AUTOSAR XML (schema 321)
# Copyright © Vector Informatik GmbH 2014
# The usage of this tool (CBD1300649 D00) is restricted to:
# - FOR THE ECU-PROJECT EPS
# - FOR THE OEM FIAT
# Please contact Vector Informatik whenever you need further information concerning the license conditions.
package /VehicleProject
  system System: fibex-element=[CCAN, EPS, EPS__CCAN_Rx, EPS__CCAN_Tx, BCM_COMMAND__CCAN, BSM1__CCAN, CFG_DATA_CODE_REQUEST__CCAN, CFG_DATA_CODE_RSP_EPS__CCAN, DIAGNOSTIC_REQUEST_EPS__CCAN, DIAGNOSTIC_REQUEST_FUNCTIONAL__CCAN, DIAGNOSTIC_RESPONSE_EPS__CCAN, GE__CCAN, GliwaMaster__CCAN, GliwaSlave__CCAN, MOT1__CCAN, MOT3__CCAN, NM_BCM__CCAN, NM_BSM__CCAN, NM_ECM__CCAN, NM_EPS__CCAN, NM_IPC__CCAN, NM_TRANSMISSION__CCAN, PDC_INFO_EPS__CCAN, STATUS_C_BCM2__CCAN, STATUS_C_IPC__CCAN, XcpMaster__CCAN, XcpSlave__CCAN, BCM_COMMAND__CCAN, BSM1__CCAN, CFG_DATA_CODE_REQUEST__CCAN, CFG_DATA_CODE_RSP_EPS__CCAN, GE__CCAN, GliwaMaster__CCAN, GliwaSlave__CCAN, MOT1__CCAN, MOT3__CCAN, PDC_INFO_EPS__CCAN, STATUS_C_BCM2__CCAN, STATUS_C_IPC__CCAN, XcpMaster__CCAN, XcpSlave__CCAN, DIAGNOSTIC_REQUEST_EPS__CCAN, DIAGNOSTIC_REQUEST_FUNCTIONAL__CCAN, DIAGNOSTIC_RESPONSE_EPS__CCAN, NM_BCM__CCAN, NM_BSM__CCAN, NM_ECM__CCAN, NM_EPS__CCAN, NM_IPC__CCAN, NM_TRANSMISSION__CCAN, DIAGNOSTIC_REQUEST_EPS_Tp__CCAN, DIAGNOSTIC_REQUEST_FUNCTIONAL_Tp__CCAN, DIAGNOSTIC_RESPONSE_EPS_Tp__CCAN, CityModeSts__STATUS_C_BCM2__CCAN, CmdIgn_FailSts__STATUS_C_BCM2__CCAN, CmdIgnSts__STATUS_C_BCM2__CCAN, CRC_B1__BSM1__CCAN, CurrentFailSts_EPS__PDC_INFO_EPS__CCAN, DES_EPS__PDC_INFO_EPS__CCAN, Digit_01__CFG_DATA_CODE_REQUEST__CCAN, Digit_01_EPS__CFG_DATA_CODE_RSP_EPS__CCAN, Digit_02__CFG_DATA_CODE_REQUEST__CCAN, Digit_02_EPS__CFG_DATA_CODE_RSP_EPS__CCAN, Digit_03__CFG_DATA_CODE_REQUEST__CCAN, Digit_03_EPS__CFG_DATA_CODE_RSP_EPS__CCAN, Digit_04__CFG_DATA_CODE_REQUEST__CCAN, Digit_04_EPS__CFG_DATA_CODE_RSP_EPS__CCAN, Digit_05__CFG_DATA_CODE_REQUEST__CCAN, Digit_05_EPS__CFG_DATA_CODE_RSP_EPS__CCAN, Digit_06__CFG_DATA_CODE_REQUEST__CCAN, Digit_06_EPS__CFG_DATA_CODE_RSP_EPS__CCAN, Digit_07__CFG_DATA_CODE_REQUEST__CCAN, Digit_07_EPS__CFG_DATA_CODE_RSP_EPS__CCAN, Digit_08__CFG_DATA_CODE_REQUEST__CCAN, Digit_08_EPS__CFG_DATA_CODE_RSP_EPS__CCAN, Digit_09__CFG_DATA_CODE_REQUEST__CCAN, Digit_09_EPS__CFG_DATA_CODE_RSP_EPS__CCAN, Digit_10__CFG_DATA_CODE_REQUEST__CCAN, Digit_10_EPS__CFG_DATA_CODE_RSP_EPS__CCAN, Digit_11__CFG_DATA_CODE_REQUEST__CCAN, Digit_11_EPS__CFG_DATA_CODE_RSP_EPS__CCAN, ElectricSteeringFailSts__GE__CCAN, ElectricSteeringLamp_FailSts__STATUS_C_IPC__CCAN, EngineStopStartSts__MOT3__CCAN, EngineSts__MOT1__CCAN, EOL_EPS__PDC_INFO_EPS__CCAN, GenericFailSts_EPS__PDC_INFO_EPS__CCAN, LwsAngle__GE__CCAN, LwsAngleType__GE__CCAN, LwsCalibration__GE__CCAN, LWSFailSts__GE__CCAN, LwsSpeed__GE__CCAN, MessageCounter_B1__BSM1__CCAN, OperationalModeSts__BCM_COMMAND__CCAN, Reserved_for_PDC_EPS__PDC_INFO_EPS__CCAN, StayActiveSource_EPS_0__PDC_INFO_EPS__CCAN, StayActiveSource_EPS_1__PDC_INFO_EPS__CCAN, StayActiveSource_EPS_10__PDC_INFO_EPS__CCAN, StayActiveSource_EPS_11__PDC_INFO_EPS__CCAN, StayActiveSource_EPS_12__PDC_INFO_EPS__CCAN, StayActiveSource_EPS_13__PDC_INFO_EPS__CCAN, StayActiveSource_EPS_14__PDC_INFO_EPS__CCAN, StayActiveSource_EPS_15__PDC_INFO_EPS__CCAN, StayActiveSource_EPS_2__PDC_INFO_EPS__CCAN, StayActiveSource_EPS_3__PDC_INFO_EPS__CCAN, StayActiveSource_EPS_4__PDC_INFO_EPS__CCAN, StayActiveSource_EPS_5__PDC_INFO_EPS__CCAN, StayActiveSource_EPS_6__PDC_INFO_EPS__CCAN, StayActiveSource_EPS_7__PDC_INFO_EPS__CCAN, StayActiveSource_EPS_8__PDC_INFO_EPS__CCAN, StayActiveSource_EPS_9__PDC_INFO_EPS__CCAN, SteeringLoad__GE__CCAN, StopStartSts__MOT3__CCAN, TotalOdometer__STATUS_C_IPC__CCAN, VehicleSpeedVSOSig__BSM1__CCAN, VehicleSpeedVSOSigFailSts__BSM1__CCAN]
package /Cluster
  can cluster CCAN: protocol-name=CAN, speed=500000, nm-lower-can-id=506724352, nm-repeat-message-state-time=4.5, nm-timeout-time=8, nm-upper-can-id=506724607, nm-wait-bus-sleep-time=1  # P3271_C-CAN [07339]_6A_R1_CR1664 | Project_3271_ProjectStandard_C-CAN [07339]
    physical channel CHNL
      frame BCM_COMMAND__CCAN: id 0xFA, to EPS, frame-length=5, can-addressing-mode=STANDARD
        pdu BCM_COMMAND__CCAN: length=40, cyclic-timing={repeating-time=0.01, starting-time=0.005}, minimum-delay=0, transmission-mode-false-timing=cyclic-timing={repeating-time=0.01, starting-time=0.005}
          signal OperationalModeSts__BCM_COMMAND__CCAN: start 7, 4 bit, big-endian, data-type=DT_OperationalModeSts, init-value=C_OperationalModeSts, transfer-property=PENDING, to EPS(timeout 2.5 s)
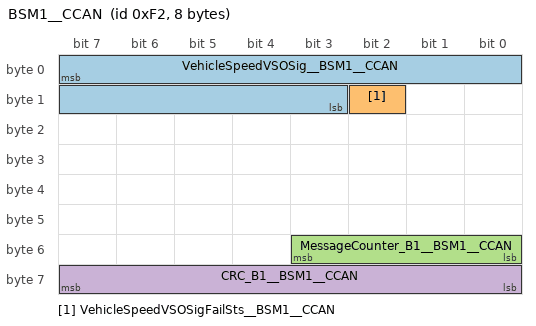
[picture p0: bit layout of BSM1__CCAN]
      frame BSM1__CCAN: id 0xF2, to EPS, frame-length=8, can-addressing-mode=STANDARD
        pdu BSM1__CCAN: length=64, cyclic-timing={repeating-time=0.01, starting-time=0}, minimum-delay=0, transmission-mode-false-timing=cyclic-timing={repeating-time=0.01, starting-time=0}
          signal VehicleSpeedVSOSig__BSM1__CCAN: start 7, 13 bit, big-endian, data-type=DT_VehicleSpeedVSOSig, init-value=C_VehicleSpeedVSOSig, transfer-property=PENDING, to EPS(timeout 2.5 s)  # It is the average vehicle speed calculated.
          signal VehicleSpeedVSOSigFailSts__BSM1__CCAN: start 10, 1 bit, big-endian, data-type=DT_VehicleSpeedVSOSigFailSts, init-value=C_VehicleSpeedVSOSigFailSts, transfer-property=PENDING, to EPS(timeout 2.5 s)  # It is the average vehicle speed fail status.
          signal MessageCounter_B1__BSM1__CCAN: start 51, 4 bit, big-endian, data-type=DT_MessageCounter_B1, init-value=C_MessageCounter_B1, transfer-property=PENDING, to EPS(timeout 2.5 s)  # This signal is a counter used for safety checks strategies. This counter is incremented of 1 (one) unit at each frame transmission.
          signal CRC_B1__BSM1__CCAN: start 63, 8 bit, big-endian, data-type=DT_CRC_B1, init-value=C_CRC_B1, transfer-property=PENDING, to EPS(timeout 2.5 s)  # CRC according to SAE J1850 standard that has to be calculated from bit 63 to bit 8 at each frame transmission.
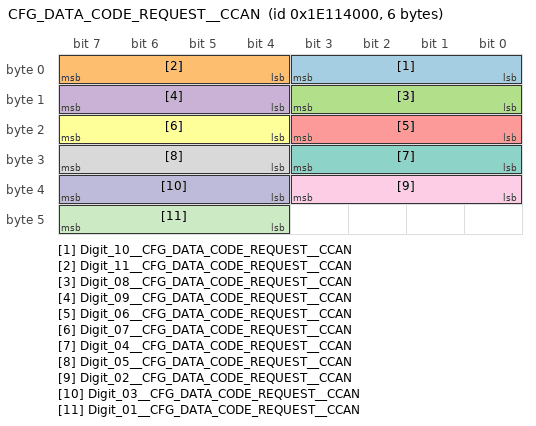
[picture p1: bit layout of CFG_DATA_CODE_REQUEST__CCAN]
      frame CFG_DATA_CODE_REQUEST__CCAN: id 0x1E114000, to EPS, frame-length=6, can-addressing-mode=EXTENDED
        pdu CFG_DATA_CODE_REQUEST__CCAN: length=48, event-controlled-timing={number-of-repeats=0, repetition-period=0}, minimum-delay=0, transmission-mode-false-timing=event-controlled-timing={number-of-repeats=0, repetition-period=0}
          signal Digit_10__CFG_DATA_CODE_REQUEST__CCAN: start 3, 4 bit, big-endian, data-type=DT_Digit_10, init-value=C_Digit_10, transfer-property=PENDING, to EPS(timeout 2.5 s)
          signal Digit_11__CFG_DATA_CODE_REQUEST__CCAN: start 7, 4 bit, big-endian, data-type=DT_Digit_11, init-value=C_Digit_11, transfer-property=PENDING, to EPS(timeout 2.5 s)
          signal Digit_08__CFG_DATA_CODE_REQUEST__CCAN: start 11, 4 bit, big-endian, data-type=DT_Digit_08, init-value=C_Digit_08, transfer-property=PENDING, to EPS(timeout 2.5 s)
          signal Digit_09__CFG_DATA_CODE_REQUEST__CCAN: start 15, 4 bit, big-endian, data-type=DT_Digit_09, init-value=C_Digit_09, transfer-property=PENDING, to EPS(timeout 2.5 s)
          signal Digit_06__CFG_DATA_CODE_REQUEST__CCAN: start 19, 4 bit, big-endian, data-type=DT_Digit_06, init-value=C_Digit_06, transfer-property=PENDING, to EPS(timeout 2.5 s)
          signal Digit_07__CFG_DATA_CODE_REQUEST__CCAN: start 23, 4 bit, big-endian, data-type=DT_Digit_07, init-value=C_Digit_07, transfer-property=PENDING, to EPS(timeout 2.5 s)
          signal Digit_04__CFG_DATA_CODE_REQUEST__CCAN: start 27, 4 bit, big-endian, data-type=DT_Digit_04, init-value=C_Digit_04, transfer-property=PENDING, to EPS(timeout 2.5 s)
          signal Digit_05__CFG_DATA_CODE_REQUEST__CCAN: start 31, 4 bit, big-endian, data-type=DT_Digit_05, init-value=C_Digit_05, transfer-property=PENDING, to EPS(timeout 2.5 s)
          signal Digit_02__CFG_DATA_CODE_REQUEST__CCAN: start 35, 4 bit, big-endian, data-type=DT_Digit_02, init-value=C_Digit_02, transfer-property=PENDING, to EPS(timeout 2.5 s)
          signal Digit_03__CFG_DATA_CODE_REQUEST__CCAN: start 39, 4 bit, big-endian, data-type=DT_Digit_03, init-value=C_Digit_03, transfer-property=PENDING, to EPS(timeout 2.5 s)
          signal Digit_01__CFG_DATA_CODE_REQUEST__CCAN: start 47, 4 bit, big-endian, data-type=DT_Digit_01, init-value=C_Digit_01, transfer-property=TRIGGERED-WITHOUT-REPETITION, to EPS(timeout 2.5 s)
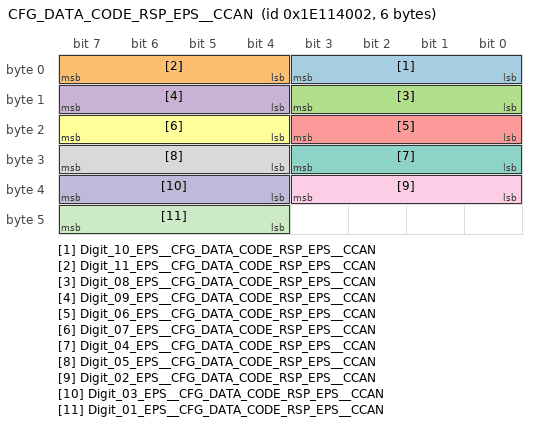
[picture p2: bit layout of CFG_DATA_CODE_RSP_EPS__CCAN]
      frame CFG_DATA_CODE_RSP_EPS__CCAN: id 0x1E114002, from EPS, frame-length=6, can-addressing-mode=EXTENDED
        pdu CFG_DATA_CODE_RSP_EPS__CCAN: length=48, event-controlled-timing={number-of-repeats=0, repetition-period=0}, minimum-delay=0, transmission-mode-false-timing=event-controlled-timing={number-of-repeats=0, repetition-period=0}
          signal Digit_10_EPS__CFG_DATA_CODE_RSP_EPS__CCAN: start 3, 4 bit, big-endian, data-type=DT_Digit_10_EPS, init-value=C_Digit_10_EPS, transfer-property=PENDING
          signal Digit_11_EPS__CFG_DATA_CODE_RSP_EPS__CCAN: start 7, 4 bit, big-endian, data-type=DT_Digit_11_EPS, init-value=C_Digit_11_EPS, transfer-property=PENDING
          signal Digit_08_EPS__CFG_DATA_CODE_RSP_EPS__CCAN: start 11, 4 bit, big-endian, data-type=DT_Digit_08_EPS, init-value=C_Digit_08_EPS, transfer-property=PENDING
          signal Digit_09_EPS__CFG_DATA_CODE_RSP_EPS__CCAN: start 15, 4 bit, big-endian, data-type=DT_Digit_09_EPS, init-value=C_Digit_09_EPS, transfer-property=PENDING
          signal Digit_06_EPS__CFG_DATA_CODE_RSP_EPS__CCAN: start 19, 4 bit, big-endian, data-type=DT_Digit_06_EPS, init-value=C_Digit_06_EPS, transfer-property=PENDING
          signal Digit_07_EPS__CFG_DATA_CODE_RSP_EPS__CCAN: start 23, 4 bit, big-endian, data-type=DT_Digit_07_EPS, init-value=C_Digit_07_EPS, transfer-property=PENDING
          signal Digit_04_EPS__CFG_DATA_CODE_RSP_EPS__CCAN: start 27, 4 bit, big-endian, data-type=DT_Digit_04_EPS, init-value=C_Digit_04_EPS, transfer-property=PENDING
          signal Digit_05_EPS__CFG_DATA_CODE_RSP_EPS__CCAN: start 31, 4 bit, big-endian, data-type=DT_Digit_05_EPS, init-value=C_Digit_05_EPS, transfer-property=PENDING
          signal Digit_02_EPS__CFG_DATA_CODE_RSP_EPS__CCAN: start 35, 4 bit, big-endian, data-type=DT_Digit_02_EPS, init-value=C_Digit_02_EPS, transfer-property=PENDING
          signal Digit_03_EPS__CFG_DATA_CODE_RSP_EPS__CCAN: start 39, 4 bit, big-endian, data-type=DT_Digit_03_EPS, init-value=C_Digit_03_EPS, transfer-property=PENDING
          signal Digit_01_EPS__CFG_DATA_CODE_RSP_EPS__CCAN: start 47, 4 bit, big-endian, data-type=DT_Digit_01_EPS, init-value=C_Digit_01_EPS, transfer-property=TRIGGERED-WITHOUT-REPETITION
      frame DIAGNOSTIC_REQUEST_EPS__CCAN: id 0x18DA30F4, to EPS, frame-length=8, can-addressing-mode=EXTENDED
        n pdu DIAGNOSTIC_REQUEST_EPS_Tp__CCAN: length=64
      frame DIAGNOSTIC_REQUEST_FUNCTIONAL__CCAN: id 0x18DBFEF4, to EPS, frame-length=8, can-addressing-mode=EXTENDED
        n pdu DIAGNOSTIC_REQUEST_FUNCTIONAL_Tp__CCAN: length=64
      frame DIAGNOSTIC_RESPONSE_EPS__CCAN: id 0x18DAF430, from EPS, frame-length=8, can-addressing-mode=EXTENDED
        n pdu DIAGNOSTIC_RESPONSE_EPS_Tp__CCAN: length=64
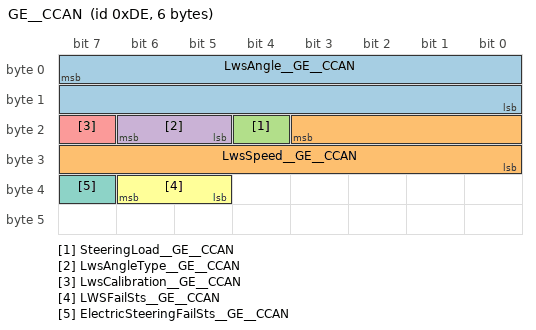
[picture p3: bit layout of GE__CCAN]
      frame GE__CCAN: id 0xDE, from EPS, frame-length=6, can-addressing-mode=STANDARD
        pdu GE__CCAN: length=48, cyclic-timing={repeating-time=0.01, starting-time=0}, minimum-delay=0, transmission-mode-false-timing=cyclic-timing={repeating-time=0.01, starting-time=0}
          signal LwsAngle__GE__CCAN: start 7, 16 bit, big-endian, data-type=DT_LwsAngle, init-value=C_LwsAngle, transfer-property=PENDING  # This signal indicates the steering angle value, counterclockwise positive.
          signal LwsSpeed__GE__CCAN: start 19, 12 bit, big-endian, data-type=DT_LwsSpeed, init-value=C_LwsSpeed, transfer-property=PENDING  # This signal indicates the steering speed value, counterclockwise positive.
          signal SteeringLoad__GE__CCAN: start 20, 1 bit, big-endian, data-type=DT_SteeringLoad, init-value=C_SteeringLoad, transfer-property=PENDING  # This signal indicates the steering load, it shows when the current draw by EPS is above an adjustable parameter indicated in [A].
          signal LwsAngleType__GE__CCAN: start 22, 2 bit, big-endian, data-type=DT_LwsAngleType, init-value=C_LwsAngleType, transfer-property=PENDING  # This signal indicates whether the angle sensor is absolute (all the possible turns/degrees) or not absolute (relative, torque only, etc.).
          signal LwsCalibration__GE__CCAN: start 23, 1 bit, big-endian, data-type=DT_LwsCalibration, init-value=C_LwsCalibration, transfer-property=PENDING  # This signal indicates if the sensor has been calibrated and therefore the steering angle value is exported over Can.
          signal LWSFailSts__GE__CCAN: start 38, 2 bit, big-endian, data-type=DT_LWSFailSts, init-value=C_LWSFailSts, transfer-property=PENDING  # This signal indicates steering angle export function failure status.
          signal ElectricSteeringFailSts__GE__CCAN: start 39, 1 bit, big-endian, data-type=DT_ElectricSteeringFailSts, init-value=C_ElectricSteeringFailSts, transfer-property=PENDING  # It indicates if system EPS has an internal fault.
      frame GliwaMaster__CCAN: id 0x7F0, to EPS, frame-length=8, can-addressing-mode=STANDARD
        pdu GliwaMaster__CCAN: length=64
      frame GliwaSlave__CCAN: id 0x7F1, from EPS, frame-length=8, can-addressing-mode=STANDARD
        pdu GliwaSlave__CCAN: length=64
      frame MOT1__CCAN: id 0xE6, to EPS, frame-length=8, can-addressing-mode=STANDARD
        pdu MOT1__CCAN: length=64, cyclic-timing={repeating-time=0.01, starting-time=0.004}, minimum-delay=0, transmission-mode-false-timing=cyclic-timing={repeating-time=0.01, starting-time=0.004}
          signal EngineSts__MOT1__CCAN: start 9, 2 bit, big-endian, data-type=DT_EngineSts, init-value=C_EngineSts, transfer-property=PENDING, to EPS(timeout 2.5 s)  # It is the current engine status
      frame MOT3__CCAN: id 0x2EE, to EPS, frame-length=8, can-addressing-mode=STANDARD
        pdu MOT3__CCAN: length=64, cyclic-timing={repeating-time=0.05, starting-time=0.03}, minimum-delay=0, transmission-mode-false-timing=cyclic-timing={repeating-time=0.05, starting-time=0.03}
          signal EngineStopStartSts__MOT3__CCAN: start 54, 2 bit, big-endian, data-type=DT_EngineStopStartSts, init-value=C_EngineStopStartSts, transfer-property=PENDING, to EPS(timeout 2.5 s)  # It is set to Engine Stop when the Engine is turned off by the Stop&Start management
          signal StopStartSts__MOT3__CCAN: start 59, 2 bit, big-endian, data-type=DT_StopStartSts, init-value=C_StopStartSts, transfer-property=PENDING, to EPS(timeout 2.5 s)  # Sent by ECM to BCM, highlight the status of the Stop&Start function.
      frame NM_BCM__CCAN: id 0x1E340000, to EPS, frame-length=2, can-addressing-mode=EXTENDED
        nm pdu NM_BCM__CCAN: length=16
      frame NM_BSM__CCAN: id 0x1E340006, to EPS, frame-length=2, can-addressing-mode=EXTENDED
        nm pdu NM_BSM__CCAN: length=16
      frame NM_ECM__CCAN: id 0x1E340001, to EPS, frame-length=2, can-addressing-mode=EXTENDED
        nm pdu NM_ECM__CCAN: length=16
      frame NM_EPS__CCAN: id 0x1E340002, from EPS, frame-length=2, can-addressing-mode=EXTENDED
        nm pdu NM_EPS__CCAN: length=16
      frame NM_IPC__CCAN: id 0x1E340003, to EPS, frame-length=2, can-addressing-mode=EXTENDED
        nm pdu NM_IPC__CCAN: length=16
      frame NM_TRANSMISSION__CCAN: id 0x1E34000B, to EPS, frame-length=2, can-addressing-mode=EXTENDED
        nm pdu NM_TRANSMISSION__CCAN: length=16
      frame PDC_INFO_EPS__CCAN: id 0x1E360002, from EPS, frame-length=3, can-addressing-mode=EXTENDED
        pdu PDC_INFO_EPS__CCAN: length=24, cyclic-timing={repeating-time=1, starting-time=0}, minimum-delay=0, transmission-mode-false-timing=cyclic-timing={repeating-time=1, starting-time=0}
          signal Reserved_for_PDC_EPS__PDC_INFO_EPS__CCAN: start 3, 4 bit, big-endian, data-type=DT_Reserved_for_PDC_EPS, init-value=C_Reserved_for_PDC_EPS, transfer-property=PENDING
          signal DES_EPS__PDC_INFO_EPS__CCAN: start 4, 1 bit, big-endian, data-type=DT_DES_EPS, init-value=C_DES_EPS, transfer-property=PENDING
          signal GenericFailSts_EPS__PDC_INFO_EPS__CCAN: start 5, 1 bit, big-endian, data-type=DT_GenericFailSts_EPS, init-value=C_GenericFailSts_EPS, transfer-property=PENDING
          signal CurrentFailSts_EPS__PDC_INFO_EPS__CCAN: start 6, 1 bit, big-endian, data-type=DT_CurrentFailSts_EPS, init-value=C_CurrentFailSts_EPS, transfer-property=PENDING
          signal EOL_EPS__PDC_INFO_EPS__CCAN: start 7, 1 bit, big-endian, data-type=DT_EOL_EPS, init-value=C_EOL_EPS, transfer-property=PENDING
          signal StayActiveSource_EPS_7__PDC_INFO_EPS__CCAN: start 8, 1 bit, big-endian, data-type=DT_StayActiveSource_EPS_7, init-value=C_StayActiveSource_EPS_7, transfer-property=PENDING
          signal StayActiveSource_EPS_6__PDC_INFO_EPS__CCAN: start 9, 1 bit, big-endian, data-type=DT_StayActiveSource_EPS_6, init-value=C_StayActiveSource_EPS_6, transfer-property=PENDING
          signal StayActiveSource_EPS_5__PDC_INFO_EPS__CCAN: start 10, 1 bit, big-endian, data-type=DT_StayActiveSource_EPS_5, init-value=C_StayActiveSource_EPS_5, transfer-property=PENDING
          signal StayActiveSource_EPS_4__PDC_INFO_EPS__CCAN: start 11, 1 bit, big-endian, data-type=DT_StayActiveSource_EPS_4, init-value=C_StayActiveSource_EPS_4, transfer-property=PENDING
          signal StayActiveSource_EPS_3__PDC_INFO_EPS__CCAN: start 12, 1 bit, big-endian, data-type=DT_StayActiveSource_EPS_3, init-value=C_StayActiveSource_EPS_3, transfer-property=PENDING
          signal StayActiveSource_EPS_2__PDC_INFO_EPS__CCAN: start 13, 1 bit, big-endian, data-type=DT_StayActiveSource_EPS_2, init-value=C_StayActiveSource_EPS_2, transfer-property=PENDING
          signal StayActiveSource_EPS_1__PDC_INFO_EPS__CCAN: start 14, 1 bit, big-endian, data-type=DT_StayActiveSource_EPS_1, init-value=C_StayActiveSource_EPS_1, transfer-property=PENDING
          signal StayActiveSource_EPS_0__PDC_INFO_EPS__CCAN: start 15, 1 bit, big-endian, data-type=DT_StayActiveSource_EPS_0, init-value=C_StayActiveSource_EPS_0, transfer-property=PENDING
          signal StayActiveSource_EPS_15__PDC_INFO_EPS__CCAN: start 16, 1 bit, big-endian, data-type=DT_StayActiveSource_EPS_15, init-value=C_StayActiveSource_EPS_15, transfer-property=PENDING
          signal StayActiveSource_EPS_14__PDC_INFO_EPS__CCAN: start 17, 1 bit, big-endian, data-type=DT_StayActiveSource_EPS_14, init-value=C_StayActiveSource_EPS_14, transfer-property=PENDING
          signal StayActiveSource_EPS_13__PDC_INFO_EPS__CCAN: start 18, 1 bit, big-endian, data-type=DT_StayActiveSource_EPS_13, init-value=C_StayActiveSource_EPS_13, transfer-property=PENDING
          signal StayActiveSource_EPS_12__PDC_INFO_EPS__CCAN: start 19, 1 bit, big-endian, data-type=DT_StayActiveSource_EPS_12, init-value=C_StayActiveSource_EPS_12, transfer-property=PENDING
          signal StayActiveSource_EPS_11__PDC_INFO_EPS__CCAN: start 20, 1 bit, big-endian, data-type=DT_StayActiveSource_EPS_11, init-value=C_StayActiveSource_EPS_11, transfer-property=PENDING
          signal StayActiveSource_EPS_10__PDC_INFO_EPS__CCAN: start 21, 1 bit, big-endian, data-type=DT_StayActiveSource_EPS_10, init-value=C_StayActiveSource_EPS_10, transfer-property=PENDING
          signal StayActiveSource_EPS_9__PDC_INFO_EPS__CCAN: start 22, 1 bit, big-endian, data-type=DT_StayActiveSource_EPS_9, init-value=C_StayActiveSource_EPS_9, transfer-property=PENDING
          signal StayActiveSource_EPS_8__PDC_INFO_EPS__CCAN: start 23, 1 bit, big-endian, data-type=DT_StayActiveSource_EPS_8, init-value=C_StayActiveSource_EPS_8, transfer-property=PENDING
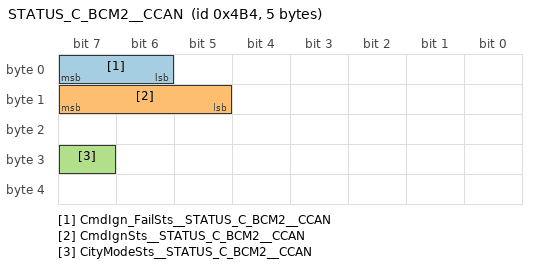
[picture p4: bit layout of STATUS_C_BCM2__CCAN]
      frame STATUS_C_BCM2__CCAN: id 0x4B4, to EPS, frame-length=5, can-addressing-mode=STANDARD
        pdu STATUS_C_BCM2__CCAN: length=40, cyclic-timing={repeating-time=0.5, starting-time=0.25}, event-controlled-timing={number-of-repeats=1, repetition-period=0.01}, minimum-delay=0.01, transmission-mode-false-timing={cyclic-timing={repeating-time=0.5, starting-time=0.25}, event-controlled-timing={number-of-repeats=1, repetition-period=0.01}}
          signal CmdIgn_FailSts__STATUS_C_BCM2__CCAN: start 7, 2 bit, big-endian, data-type=DT_CmdIgn_FailSts, init-value=C_CmdIgn_FailSts, transfer-property=TRIGGERED-ON-CHANGE, to EPS(timeout 2.5 s)
          signal CmdIgnSts__STATUS_C_BCM2__CCAN: start 15, 3 bit, big-endian, data-type=DT_CmdIgnSts, init-value=C_CmdIgnSts, transfer-property=TRIGGERED-ON-CHANGE, to EPS(timeout 2.5 s)  # Used to give information about the key selector position
          signal CityModeSts__STATUS_C_BCM2__CCAN: start 31, 1 bit, big-endian, data-type=DT_CityModeSts, init-value=C_CityModeSts, transfer-property=TRIGGERED-ON-CHANGE, to EPS(timeout 2.5 s)  # It is the information about city/eco/power/sport mode
      frame STATUS_C_IPC__CCAN: id 0x419, to EPS, frame-length=8, can-addressing-mode=STANDARD
        pdu STATUS_C_IPC__CCAN: length=64, cyclic-timing={repeating-time=0.1, starting-time=0.055}, event-controlled-timing={number-of-repeats=0, repetition-period=0}, minimum-delay=0.01, transmission-mode-false-timing={cyclic-timing={repeating-time=0.1, starting-time=0.055}, event-controlled-timing={number-of-repeats=0, repetition-period=0}}
          signal ElectricSteeringLamp_FailSts__STATUS_C_IPC__CCAN: start 1, 2 bit, big-endian, data-type=DT_ElectricSteeringLamp_FailSts, init-value=C_ElectricSteeringLamp_FailSts, transfer-property=PENDING, to EPS(timeout 2.5 s)  # This signal communicates the status of the related lamp.
          signal TotalOdometer__STATUS_C_IPC__CCAN: start 31, 20 bit, big-endian, data-type=DT_TotalOdometer, init-value=C_TotalOdometer, transfer-property=PENDING, to EPS
      frame XcpMaster__CCAN: id 0x695, to EPS, frame-length=8, can-addressing-mode=STANDARD
        pdu XcpMaster__CCAN: length=64
      frame XcpSlave__CCAN: id 0x6E5, from EPS, frame-length=8, can-addressing-mode=STANDARD
        pdu XcpSlave__CCAN: length=64
      pdu triggering PT_DIAGNOSTIC_REQUEST_EPS: pdu=DIAGNOSTIC_REQUEST_EPS__CCAN, to EPS
      pdu triggering PT_DIAGNOSTIC_REQUEST_FUNCTIONAL: pdu=DIAGNOSTIC_REQUEST_FUNCTIONAL__CCAN, to EPS
      pdu triggering PT_DIAGNOSTIC_RESPONSE_EPS: pdu=DIAGNOSTIC_RESPONSE_EPS__CCAN, from EPS
      tp address TA_0x0030: tp-address=48
      tp address TA_0x00F4: tp-address=244
      tp address TA_0x00FE: tp-address=254
      tp-channels:
        addressing-format=STANDARD, data-pdu=DIAGNOSTIC_REQUEST_FUNCTIONAL_Tp__CCAN, multicast-addressing=true, multicast=TA_0x00FE, source=TN_0x00F4, ta-type=FUNCTIONAL, target=TN_EPS, tp-sdu=DIAGNOSTIC_REQUEST_FUNCTIONAL__CCAN
        addressing-format=STANDARD, data-pdu=DIAGNOSTIC_RESPONSE_EPS_Tp__CCAN, flow-control-pdu=DIAGNOSTIC_REQUEST_EPS_Tp__CCAN, multicast-addressing=false, source=TN_0x0030, ta-type=PHYSICAL, target=TN_0x00F4, tp-sdu=DIAGNOSTIC_RESPONSE_EPS__CCAN
        addressing-format=STANDARD, data-pdu=DIAGNOSTIC_REQUEST_EPS_Tp__CCAN, flow-control-pdu=DIAGNOSTIC_RESPONSE_EPS_Tp__CCAN, multicast-addressing=false, source=TN_0x00F4, ta-type=PHYSICAL, target=TN_0x0030, tp-sdu=DIAGNOSTIC_REQUEST_EPS__CCAN
      can tp node TN_0x0030: connector=CN_CCAN, tp-address=TA_0x0030
      can tp node TN_0x00F4: tp-address=TA_0x00F4
      can tp node TN_EPS: connector=CN_CCAN
package /ECU
  ecu instance EPS: associated-i-pdu-group=[EPS__CCAN_Rx, EPS__CCAN_Tx], com-processing-period=0.001
    can communication controller CT_CCAN: nm-msg-cycle-offset=0.06, nm-msg-reduced-time=0.85
    can communication connector CN_CCAN: channel=CHNL, comm-controller=CT_CCAN, nm-address=2
package /IPDUGroup
  i pdu group EPS__CCAN_Rx: communication-direction=IN, i-pdu=[BCM_COMMAND__CCAN, BSM1__CCAN, CFG_DATA_CODE_REQUEST__CCAN, MOT1__CCAN, MOT3__CCAN, STATUS_C_BCM2__CCAN, STATUS_C_IPC__CCAN]
  i pdu group EPS__CCAN_Tx: communication-direction=OUT, i-pdu=[CFG_DATA_CODE_RSP_EPS__CCAN, GE__CCAN, PDC_INFO_EPS__CCAN]
package /PDU
  dcm i pdu DIAGNOSTIC_REQUEST_EPS__CCAN: length=64
  dcm i pdu DIAGNOSTIC_REQUEST_FUNCTIONAL__CCAN: length=56
  dcm i pdu DIAGNOSTIC_RESPONSE_EPS__CCAN: length=64
package /DataType
  25 x boolean type:
    DT_CityModeSts: compu {0=Cx0_Normal, 1=Cx1_City}
    DT_CurrentFailSts_EPS: compu {0=Cx0_No_Fail_Present, 1=Cx1_Fail_Present}
    DT_DES_EPS: compu {0=Cx0_No_Busoff, 1=Cx1_Busoff_Occurred}
    DT_ElectricSteeringFailSts: compu {0=Cx0_Fail_Not_Present, 1=Cx1_Fail_Present}
    DT_EOL_EPS: compu {0=Cx0_No_EOL_Programming, 1=Cx1_EOL_Programming}
    DT_GenericFailSts_EPS: compu {0=Cx0_No_Fail_Present, 1=Cx1_Fail_Present}
    DT_LwsCalibration: compu {0=Cx0_Not_calibrated, 1=Cx1_Calibrated}
    DT_StayActiveSource_EPS_0: compu {0=Cx0_Active, 1=Cx1_NotActive}
    DT_StayActiveSource_EPS_1: compu {0=Cx0_Active, 1=Cx1_NotActive}
    DT_StayActiveSource_EPS_{10..15}: compu {0=Cx0_Active, 1=Cx1_NotActive}
    DT_StayActiveSource_EPS_{2..9}: compu {0=Cx0_Active, 1=Cx1_NotActive}
    DT_SteeringLoad: compu {0=Cx0_Above_Threshold, 1=Cx1_Below_Threshold}
    DT_VehicleSpeedVSOSigFailSts: compu {0=Cx0_Fail_not_present, 1=Cx1_Fail_present}
  38 x integer type, all with lower-limit=0:
    DT_CmdIgn_FailSts: compu {0=Cx0_Fail_Not_Present, 1=Cx1_Fail_Present, 3=Cx3_SNA}, upper-limit=3
      invalid-value:
        integer literal DT_CmdIgn_FailSts: type=DT_CmdIgn_FailSts, value=3
    DT_CmdIgnSts: compu {0=Cx0_Initialization, 1=Cx1_IGN_LK, 3=Cx3_ACC, 4=Cx4_RUN, 5=Cx5_START, 7=Cx7_SNA}, upper-limit=7
      invalid-value:
        integer literal DT_CmdIgnSts: type=DT_CmdIgnSts, value=7
    DT_CRC_B1: upper-limit=255
    DT_Digit_01: upper-limit=15
    DT_Digit_01_EPS: upper-limit=15
    DT_Digit_02: upper-limit=15
    DT_Digit_02_EPS: upper-limit=15
    DT_Digit_03: upper-limit=15
    DT_Digit_03_EPS: upper-limit=15
    DT_Digit_04: upper-limit=15
    DT_Digit_04_EPS: upper-limit=15
    DT_Digit_05: upper-limit=15
    DT_Digit_05_EPS: upper-limit=15
    DT_Digit_06: upper-limit=15
    DT_Digit_06_EPS: upper-limit=15
    DT_Digit_07: upper-limit=15
    DT_Digit_07_EPS: upper-limit=15
    DT_Digit_08: upper-limit=15
    DT_Digit_08_EPS: upper-limit=15
    DT_Digit_09: upper-limit=15
    DT_Digit_09_EPS: upper-limit=15
    DT_Digit_10: upper-limit=15
    DT_Digit_10_EPS: upper-limit=15
    DT_Digit_11: upper-limit=15
    DT_Digit_11_EPS: upper-limit=15
    DT_ElectricSteeringLamp_FailSts: compu {0=Cx0_OFF_Fail_not_present, 1=Cx1_OFF_Fail_present, 2=Cx2_ON_Fail_not_present, 3=Cx3_Not_used}, upper-limit=3
    DT_EngineStopStartSts: compu {0=Cx0_Engine_Stop, 1=Cx1_Engine_Not_in_Stop, 2=Cx2_Engine_Stall, 3=Cx3_Engine_Stopping}, upper-limit=3
    DT_EngineSts: compu {0=Cx0_Engine_Off, 1=Cx1_Engine_Cranking, 2=Cx2_Engine_On, 3=Cx3_SNA}, upper-limit=3
      invalid-value:
        integer literal DT_EngineSts: type=DT_EngineSts, value=3
    DT_LwsAngle: compu {65535=CxFFFF_SNA, phys=raw*0.1-720; unit °}, upper-limit=65535  # Source signal range: [0,14400]
      invalid-value:
        integer literal DT_LwsAngle: type=DT_LwsAngle, value=65535
    DT_LwsAngleType: compu {0=Cx0_Absolute, 1=Cx1_Relative, 3=Cx3_SNA}, upper-limit=3  # Source signal range: [0,1]
      invalid-value:
        integer literal DT_LwsAngleType: type=DT_LwsAngleType, value=3
    DT_LWSFailSts: compu {0=Cx0_Fail_not_Present, 1=Cx1_Fail_Present_Ignition_Latched, 2=Cx2_Fail_Present_Recoverable, 3=Cx3_Fail_Present_Battery_Disconnection}, upper-limit=3
    DT_LwsSpeed: compu {4095=CxFFF_SNA, phys=raw-2000; unit °/s}, upper-limit=4095
      invalid-value:
        integer literal DT_LwsSpeed: type=DT_LwsSpeed, value=4095
    DT_MessageCounter_B1: upper-limit=15
    DT_OperationalModeSts: compu {0=Cx0_Initialization, 1=Cx1_Ignition_Off_WithoutKey, 2=Cx2_Ignition_Off, 3=Cx3_Ignition_Acc, 4=Cx4_Ignition_On, 5=Cx5_Ignition_Pre_Start, 6=Cx6_Ignition_Start, 7=Cx7_Ignition_Cranking, 8=Cx8_Ignition_On_EngOn, 9=Cx9_Ignition_Pre_Acc, 10=CxA_Ignition_Pre_Off, 11=CxB_Automatic_Cranking, 12=CxC_Automatic_Stop, 13=CxD_Key_Authenticated, 14=CxE_Not_Used, 15=CxF_SNA}, upper-limit=15
      invalid-value:
        integer literal DT_OperationalModeSts: type=DT_OperationalModeSts, value=15
    DT_Reserved_for_PDC_EPS: upper-limit=15
    DT_StopStartSts: compu {0=Cx0_OFF, 1=Cx1_ON, 2=Cx2_Functional_Disable_Request, 3=Cx3_Safety_Disable_Request}, upper-limit=3
    DT_TotalOdometer: compu {; unit km}, upper-limit=1048575
    DT_VehicleSpeedVSOSig: compu {8191=Cx1FFF_SNA, phys=raw*0.0625; unit Km/h}, upper-limit=8191
      invalid-value:
        integer literal DT_VehicleSpeedVSOSig: type=DT_VehicleSpeedVSOSig, value=8191
package /DataType/Unit
  4 x unit:
    U_d: display-name=°
    U_dYs: display-name=°/s
    U_km: display-name=km
    U_KmYh: display-name=Km/h
package /Constant
  63 x constant specification:
    C_CityModeSts
      value:
        boolean literal C_CityModeSts: type=DT_CityModeSts, value=false
    C_CurrentFailSts_EPS
      value:
        boolean literal C_CurrentFailSts_EPS: type=DT_CurrentFailSts_EPS, value=false
    C_DES_EPS
      value:
        boolean literal C_DES_EPS: type=DT_DES_EPS, value=false
    C_ElectricSteeringFailSts
      value:
        boolean literal C_ElectricSteeringFailSts: type=DT_ElectricSteeringFailSts, value=false
    C_EOL_EPS
      value:
        boolean literal C_EOL_EPS: type=DT_EOL_EPS, value=false
    C_GenericFailSts_EPS
      value:
        boolean literal C_GenericFailSts_EPS: type=DT_GenericFailSts_EPS, value=false
    C_LwsCalibration
      value:
        boolean literal C_LwsCalibration: type=DT_LwsCalibration, value=false
    C_StayActiveSource_EPS_0
      value:
        boolean literal C_StayActiveSource_EPS_0: type=DT_StayActiveSource_EPS_0, value=false
    C_StayActiveSource_EPS_1
      value:
        boolean literal C_StayActiveSource_EPS_1: type=DT_StayActiveSource_EPS_1, value=false
    C_StayActiveSource_EPS_10
      value:
        boolean literal C_StayActiveSource_EPS_10: type=DT_StayActiveSource_EPS_10, value=false
    C_StayActiveSource_EPS_11
      value:
        boolean literal C_StayActiveSource_EPS_11: type=DT_StayActiveSource_EPS_11, value=false
    C_StayActiveSource_EPS_12
      value:
        boolean literal C_StayActiveSource_EPS_12: type=DT_StayActiveSource_EPS_12, value=false
    C_StayActiveSource_EPS_13
      value:
        boolean literal C_StayActiveSource_EPS_13: type=DT_StayActiveSource_EPS_13, value=false
    C_StayActiveSource_EPS_14
      value:
        boolean literal C_StayActiveSource_EPS_14: type=DT_StayActiveSource_EPS_14, value=false
    C_StayActiveSource_EPS_15
      value:
        boolean literal C_StayActiveSource_EPS_15: type=DT_StayActiveSource_EPS_15, value=false
    C_StayActiveSource_EPS_2
      value:
        boolean literal C_StayActiveSource_EPS_2: type=DT_StayActiveSource_EPS_2, value=false
    C_StayActiveSource_EPS_3
      value:
        boolean literal C_StayActiveSource_EPS_3: type=DT_StayActiveSource_EPS_3, value=false
    C_StayActiveSource_EPS_4
      value:
        boolean literal C_StayActiveSource_EPS_4: type=DT_StayActiveSource_EPS_4, value=false
    C_StayActiveSource_EPS_5
      value:
        boolean literal C_StayActiveSource_EPS_5: type=DT_StayActiveSource_EPS_5, value=false
    C_StayActiveSource_EPS_6
      value:
        boolean literal C_StayActiveSource_EPS_6: type=DT_StayActiveSource_EPS_6, value=false
    C_StayActiveSource_EPS_7
      value:
        boolean literal C_StayActiveSource_EPS_7: type=DT_StayActiveSource_EPS_7, value=false
    C_StayActiveSource_EPS_8
      value:
        boolean literal C_StayActiveSource_EPS_8: type=DT_StayActiveSource_EPS_8, value=false
    C_StayActiveSource_EPS_9
      value:
        boolean literal C_StayActiveSource_EPS_9: type=DT_StayActiveSource_EPS_9, value=false
    C_SteeringLoad
      value:
        boolean literal C_SteeringLoad: type=DT_SteeringLoad, value=true
    C_VehicleSpeedVSOSigFailSts
      value:
        boolean literal C_VehicleSpeedVSOSigFailSts: type=DT_VehicleSpeedVSOSigFailSts, value=false
    C_CmdIgn_FailSts
      value:
        integer literal C_CmdIgn_FailSts: type=DT_CmdIgn_FailSts, value=0
    C_CmdIgnSts
      value:
        integer literal C_CmdIgnSts: type=DT_CmdIgnSts, value=0
    C_CRC_B1
      value:
        integer literal C_CRC_B1: type=DT_CRC_B1, value=0
    C_Digit_01
      value:
        integer literal C_Digit_01: type=DT_Digit_01, value=0
    C_Digit_01_EPS
      value:
        integer literal C_Digit_01_EPS: type=DT_Digit_01_EPS, value=0
    C_Digit_02
      value:
        integer literal C_Digit_02: type=DT_Digit_02, value=0
    C_Digit_02_EPS
      value:
        integer literal C_Digit_02_EPS: type=DT_Digit_02_EPS, value=0
    C_Digit_03
      value:
        integer literal C_Digit_03: type=DT_Digit_03, value=0
    C_Digit_03_EPS
      value:
        integer literal C_Digit_03_EPS: type=DT_Digit_03_EPS, value=0
    C_Digit_04
      value:
        integer literal C_Digit_04: type=DT_Digit_04, value=0
    C_Digit_04_EPS
      value:
        integer literal C_Digit_04_EPS: type=DT_Digit_04_EPS, value=0
    C_Digit_05
      value:
        integer literal C_Digit_05: type=DT_Digit_05, value=0
    C_Digit_05_EPS
      value:
        integer literal C_Digit_05_EPS: type=DT_Digit_05_EPS, value=0
    C_Digit_06
      value:
        integer literal C_Digit_06: type=DT_Digit_06, value=0
    C_Digit_06_EPS
      value:
        integer literal C_Digit_06_EPS: type=DT_Digit_06_EPS, value=0
    C_Digit_07
      value:
        integer literal C_Digit_07: type=DT_Digit_07, value=0
    C_Digit_07_EPS
      value:
        integer literal C_Digit_07_EPS: type=DT_Digit_07_EPS, value=0
    C_Digit_08
      value:
        integer literal C_Digit_08: type=DT_Digit_08, value=0
    C_Digit_08_EPS
      value:
        integer literal C_Digit_08_EPS: type=DT_Digit_08_EPS, value=0
    C_Digit_09
      value:
        integer literal C_Digit_09: type=DT_Digit_09, value=0
    C_Digit_09_EPS
      value:
        integer literal C_Digit_09_EPS: type=DT_Digit_09_EPS, value=0
    C_Digit_10
      value:
        integer literal C_Digit_10: type=DT_Digit_10, value=0
    C_Digit_10_EPS
      value:
        integer literal C_Digit_10_EPS: type=DT_Digit_10_EPS, value=0
    C_Digit_11
      value:
        integer literal C_Digit_11: type=DT_Digit_11, value=0
    C_Digit_11_EPS
      value:
        integer literal C_Digit_11_EPS: type=DT_Digit_11_EPS, value=0
    C_ElectricSteeringLamp_FailSts
      value:
        integer literal C_ElectricSteeringLamp_FailSts: type=DT_ElectricSteeringLamp_FailSts, value=0
    C_EngineStopStartSts
      value:
        integer literal C_EngineStopStartSts: type=DT_EngineStopStartSts, value=1
    C_EngineSts
      value:
        integer literal C_EngineSts: type=DT_EngineSts, value=3
    C_LwsAngle
      value:
        integer literal C_LwsAngle: type=DT_LwsAngle, value=0
    C_LwsAngleType
      value:
        integer literal C_LwsAngleType: type=DT_LwsAngleType, value=0
    C_LWSFailSts
      value:
        integer literal C_LWSFailSts: type=DT_LWSFailSts, value=0
    C_LwsSpeed
      value:
        integer literal C_LwsSpeed: type=DT_LwsSpeed, value=0
    C_MessageCounter_B1
      value:
        integer literal C_MessageCounter_B1: type=DT_MessageCounter_B1, value=0
    C_OperationalModeSts
      value:
        integer literal C_OperationalModeSts: type=DT_OperationalModeSts, value=0
    C_Reserved_for_PDC_EPS
      value:
        integer literal C_Reserved_for_PDC_EPS: type=DT_Reserved_for_PDC_EPS, value=0
    C_StopStartSts
      value:
        integer literal C_StopStartSts: type=DT_StopStartSts, value=0
    C_TotalOdometer
      value:
        integer literal C_TotalOdometer: type=DT_TotalOdometer, value=0
    C_VehicleSpeedVSOSig
      value:
        integer literal C_VehicleSpeedVSOSig: type=DT_VehicleSpeedVSOSig, value=0
